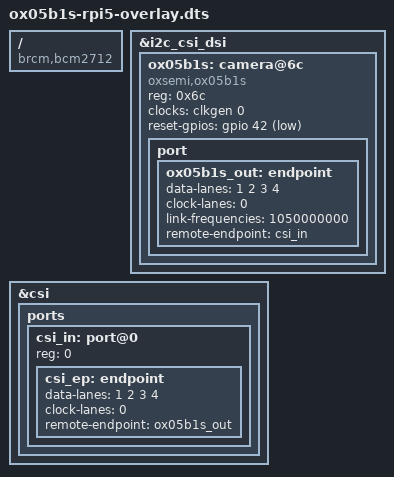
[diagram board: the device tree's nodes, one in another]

/dts-v1/;
/plugin/;

/ {
    compatible = "brcm,bcm2712";
    fragment@0 {
        target = <&i2c_csi_dsi>;
        __overlay__ {
            #address-cells = <1>;
            #size-cells = <0>;

            ox05b1s: camera@6c {
                compatible = "oxsemi,ox05b1s";
                reg = <0x6c>;
                clocks = <&clkgen 0>;
                clock-names = "xvclk";
                reset-gpios = <&gpio 42 GPIO_ACTIVE_LOW>; /* adjust */
                /* All supplies removed for brevity */

                port {
                    ox05b1s_out: endpoint {
                        data-lanes = <1 2 3 4>;
                        clock-lanes = <0>;
                        link-frequencies = /bits/ 64 <1050000000>;
                        remote-endpoint = <&csi_in>;
                    };
                };
            };
        };
    };

    fragment@1 {
        target = <&csi>;
        __overlay__ {
            status = "okay";
            ports {
                csi_in: port@0 {
                    reg = <0>;
                    csi_ep: endpoint {
                        data-lanes = <1 2 3 4>;
                        clock-lanes = <0>;
                        remote-endpoint = <&ox05b1s_out>;
                    };
                };
            };
        };
    };
};
